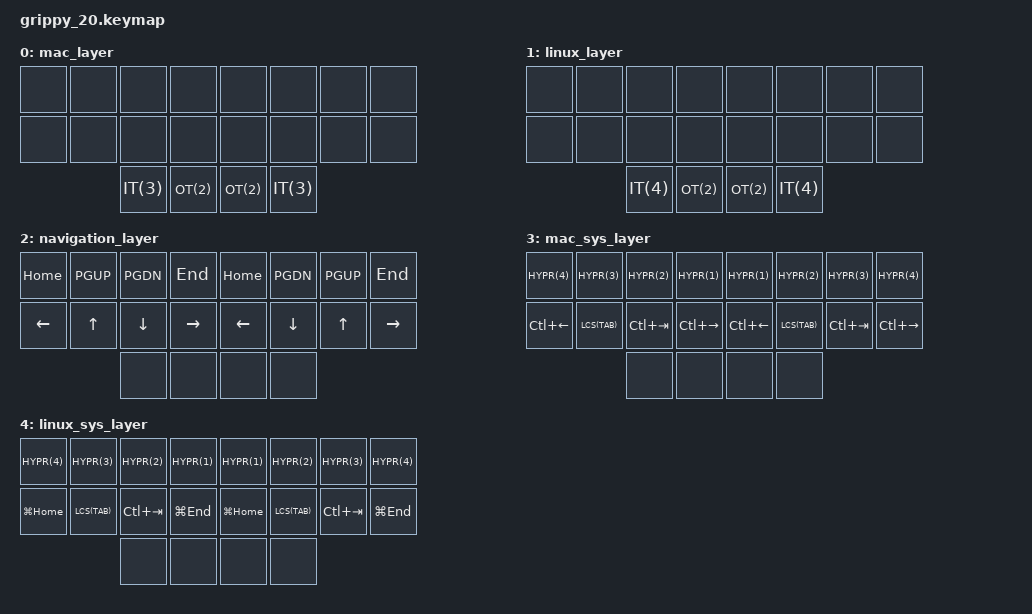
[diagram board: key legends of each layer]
#include <behaviors.dtsi>
#include <dt-bindings/zmk/bt.h>
#include <dt-bindings/zmk/dynamic_macro.h>
#include <dt-bindings/zmk/keys.h>
#include <dt-bindings/zmk/outputs.h>

// OS LAYERS
#define MACOS       0
#define LINUX       1
#define BASE    MACOS LINUX
#define DEFAULT MACOS

// TIMEOUTS
#define TIMEOUT_SHORT    20
#define TIMEOUT_NORMAL   50
#define TIMEOUT_LONG    250
#define TIMEOUT_XLONG  1500

// CONFIG
#define COMBO_TIMEOUT    TIMEOUT_NORMAL
#define CHORD_TIMEOUT    TIMEOUT_NORMAL
#define STICKY_TIMEOUT   TIMEOUT_XLONG
#define TAPPING_TERM_MS  TIMEOUT_LONG

// LEFT SIDE
#define TLI  3 // TOP
#define TLM  2 // TOP
#define TLR  1 // TOP
#define TLP  0 // TOP
#define BLI 11 // BOTTOM
#define BLM 10 // BOTTOM
#define BLR  9 // BOTTOM
#define BLP  8 // BOTTOM
#define LOT 17 // O-THUMB
#define LIT 16 // I-THUMB

// RIGHT SIDE
#define TRI  4 // TOP
#define TRM  5 // TOP
#define TRR  6 // TOP
#define TRP  7 // TOP
#define BRI 12 // BOTTOM
#define BRM 13 // BOTTOM
#define BRR 14 // BOTTOM
#define BRP 15 // BOTTOM
#define ROT 18 // O-THUMB
#define RIT 19 // I-THUMB

/ {
  behaviors {
    sk: sticky_key {
      compatible = "zmk,behavior-sticky-key";
      release-after-ms = <STICKY_TIMEOUT>;
      quick-release;
      ignore-modifiers;
    };

    ht: hold_tap {
      compatible = "zmk,behavior-hold-tap";
      #binding-cells = <2>;
      flavor = "tap-preferred";
      tapping-term-ms = <TAPPING_TERM_MS>;
      quick-tap-ms = <TAPPING_TERM_MS>;
      require-prior-idle-ms = <125>;
      bindings = <&mo &kp>;
    };
  };

  macros {
    // MACROS TO SET THE OS LAYER WITH THE BLUETOOTH PROFILE
    bt_profile_0: bt_profile_0 {
      compatible = "zmk,behavior-macro";
      #binding-cells = <0>;
      bindings = <&macro_tap &bt BT_SEL 0>, <&macro_tap &to DEFAULT>;
    };

    bt_profile_1: bt_profile_1 {
      compatible = "zmk,behavior-macro";
      #binding-cells = <0>;
      bindings = <&macro_tap &bt BT_SEL 1>, <&macro_tap &to LINUX>;
    };

    bt_profile_2: bt_profile_2 {
      compatible = "zmk,behavior-macro";
      #binding-cells = <0>;
      bindings = <&macro_tap &bt BT_SEL 2>, <&macro_tap &to DEFAULT>;
    };

    bt_profile_3: bt_profile_3 {
      compatible = "zmk,behavior-macro";
      #binding-cells = <0>;
      bindings = <&macro_tap &bt BT_SEL 3>, <&macro_tap &to DEFAULT>;
    };

    #include "macros.def"
  };

  combos {
    compatible = "zmk,combos";
    #include "combos.def"
    #include "chords.def"
  };

  keymap {
    compatible = "zmk,keymap";

    #define HYPR(K) LA(LG(K))
    #define IT(LAYER) &ht LAYER BSPC
    #define OT(LAYER) &ht LAYER SPACE

    mac_layer {
      bindings = <
        &none &none &none  &none    &none  &none &none &none
        &none &none &none  &none    &none  &none &none &none
        /*       */ IT(3)  OT(2)    OT(2)  IT(3)
      >;
    };

    linux_layer {
      bindings = <
        &none &none &none  &none    &none  &none &none &none
        &none &none &none  &none    &none  &none &none &none
        /*       */ IT(4)  OT(2)    OT(2)  IT(4)
      >;
    };

    navigation_layer {
      /* text navigation */
      bindings = <
        &kp HOME &kp PGUP &kp PGDN &kp END      &kp HOME &kp PGDN &kp PGUP &kp END
        &kp LEFT &kp UP   &kp DOWN &kp RIGHT    &kp LEFT &kp DOWN &kp UP   &kp RIGHT
        /*             */ &none    &none        &none    &none
      >;
    };

    mac_sys_layer {
      /* defines macos-specific navigation keys */
      bindings = <
        &kp HYPR(4)  &kp HYPR(3)  &kp HYPR(2) &kp HYPR(1)      &kp HYPR(1)  &kp HYPR(2)  &kp HYPR(3)  &kp HYPR(4) 
        &kp LC(LEFT) &kp LCS(TAB) &kp LC(TAB) &kp LC(RIGHT)    &kp LC(LEFT) &kp LCS(TAB) &kp LC(TAB)  &kp LC(RIGHT)
        /*                     */ &none       &none            &none        &none
      >;
    };

    linux_sys_layer {
      /* defines linux-specific navigation keys */
      bindings = <
        &kp HYPR(4)  &kp HYPR(3)  &kp HYPR(2) &kp HYPR(1)      &kp HYPR(1)  &kp HYPR(2)  &kp HYPR(3)  &kp HYPR(4) 
        &kp LG(HOME) &kp LCS(TAB) &kp LC(TAB) &kp LG(END)      &kp LG(HOME) &kp LCS(TAB) &kp LC(TAB)  &kp LG(END)
        /*                     */ &none       &none            &none        &none
      >;
    };
  };
};
